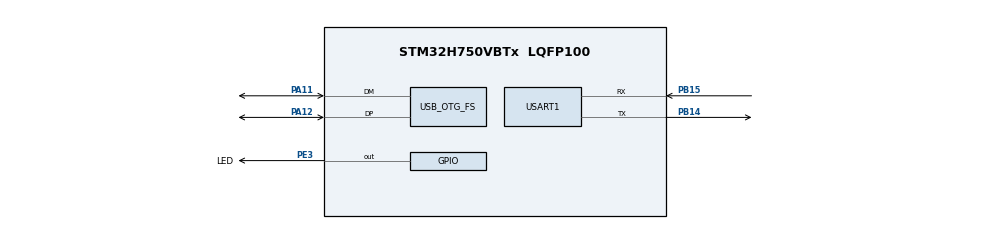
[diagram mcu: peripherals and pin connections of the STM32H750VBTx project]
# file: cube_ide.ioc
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FREERTOS.Tasks01=defaultTask,24,512,StartDefaultTask,Default,NULL,Dynamic,NULL,NULL
FREERTOS.configMINIMAL_STACK_SIZE=256
FREERTOS.configUSE_NEWLIB_REENTRANT=1
Mcu.Family=STM32H7
Mcu.Name=STM32H750VBTx
Mcu.Package=LQFP100
NVIC.OTG_FS_IRQn=true\:5\:0\:false\:false\:true\:true\:false\:true\:true
NVIC.PriorityGroup=NVIC_PRIORITYGROUP_4
PA11.Mode=Device_Only
PA11.Signal=USB_OTG_FS_DM
PA12.Mode=Device_Only
PA12.Signal=USB_OTG_FS_DP
PA13\ (JTMS/SWDIO).Mode=Serial_Wire
PA13\ (JTMS/SWDIO).Signal=DEBUG_JTMS-SWDIO
PA14\ (JTCK/SWCLK).Mode=Serial_Wire
PA14\ (JTCK/SWCLK).Signal=DEBUG_JTCK-SWCLK
PB14.Mode=Asynchronous
PB14.Signal=USART1_TX
PB15.Mode=Asynchronous
PB15.Signal=USART1_RX
PE3.GPIO_Label=LED
PE3.Signal=GPIO_Output
PH0-OSC_IN\ (PH0).Mode=HSE-External-Oscillator
PH0-OSC_IN\ (PH0).Signal=RCC_OSC_IN
PH1-OSC_OUT\ (PH1).Mode=HSE-External-Oscillator
PH1-OSC_OUT\ (PH1).Signal=RCC_OSC_OUT
ProjectManager.HeapSize=0x1000
ProjectManager.StackSize=0x400
ProjectManager.TargetToolchain=STM32CubeIDE
RCC.ADCFreq_Value=50000000
RCC.APB1Freq_Value=120000000
RCC.APB2Freq_Value=120000000
RCC.APB3Freq_Value=120000000
RCC.APB4Freq_Value=120000000
RCC.CortexFreq_Value=60000000
RCC.Cortex_Div=SYSTICK_CLKSOURCE_HCLK_DIV8
RCC.DIVM1=5
RCC.DIVM2=1
RCC.DIVM3=5
RCC.DIVN1=192
RCC.DIVN2=4
RCC.DIVN3=96
RCC.DIVQ3=10
RCC.HCLKFreq_Value=120000000
RCC.HPRE=RCC_HCLK_DIV4
RCC.PLL2FRACN=0
RCC.PLL3FRACN=0
RCC.PLLFRACN=0
RCC.PLLSourceVirtual=RCC_PLLSOURCE_HSE
RCC.ProductRev=revV
RCC.SYSCLKFreq_VALUE=480000000
RCC.SYSCLKSource=RCC_SYSCLKSOURCE_PLLCLK
RCC.USBCLockSelection=RCC_USBCLKSOURCE_PLL3
RCC.USBFreq_Value=48000000
USART1.VirtualMode-Asynchronous=VM_ASYNC
USB_DEVICE.CLASS_NAME_FS=CDC
USB_DEVICE.VirtualMode-CDC_FS=Cdc
USB_DEVICE.VirtualModeFS=Cdc_FS
USB_OTG_FS.VirtualMode=Device_Only
VP_FREERTOS_VS_CMSIS_V2.Mode=CMSIS_V2
VP_USB_DEVICE_VS_USB_DEVICE_CDC_FS.Mode=CDC_FS
board=custom

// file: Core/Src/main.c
/* USER CODE BEGIN Header */
/**
  ******************************************************************************
  * @file           : main.c
  * @brief          : Main program body
  ******************************************************************************
  * @attention
  *
  * Copyright (c) 2023 STMicroelectronics.
  * All rights reserved.
  *
  * This software is licensed under terms that can be found in the LICENSE file
  * in the root directory of this software component.
  * If no LICENSE file comes with this software, it is provided AS-IS.
  *
  ******************************************************************************
  */
/* USER CODE END Header */
#include "main.h"
#include "cmsis_os.h"
#include "usart.h"
#include "usb_device.h"
#include "gpio.h"

void SystemClock_Config(void);
void MX_FREERTOS_Init(void);

/* USER CODE BEGIN 0 */

void SysTick_Handler();
/* USER CODE END 0 */

int main(void)
{

  /* MCU Configuration--------------------------------------------------------*/

  /* Reset of all peripherals, Initializes the Flash interface and the Systick. */
  HAL_Init();

  /* Configure the system clock */
  SystemClock_Config();

  /* Initialize all configured peripherals */
  MX_GPIO_Init();
  MX_USART1_UART_Init();

  /* Init scheduler */
  osKernelInitialize();  /* Call init function for freertos objects (in freertos.c) */
  MX_FREERTOS_Init();

  /* Start scheduler */
  osKernelStart();
  /* We should never get here as control is now taken by the scheduler */
  /* Infinite loop */
  while (1)
  {

  }
}

void SystemClock_Config(void)
{
  RCC_OscInitTypeDef RCC_OscInitStruct = {0};
  RCC_ClkInitTypeDef RCC_ClkInitStruct = {0};

  /** Supply configuration update enable
  */
  HAL_PWREx_ConfigSupply(PWR_LDO_SUPPLY);

  /** Configure the main internal regulator output voltage
  */
  __HAL_PWR_VOLTAGESCALING_CONFIG(PWR_REGULATOR_VOLTAGE_SCALE1);

  while(!__HAL_PWR_GET_FLAG(PWR_FLAG_VOSRDY)) {}

  /** Initializes the RCC Oscillators according to the specified parameters
  * in the RCC_OscInitTypeDef structure.
  */
  RCC_OscInitStruct.OscillatorType = RCC_OSCILLATORTYPE_HSE;
  RCC_OscInitStruct.HSEState = RCC_HSE_ON;
  RCC_OscInitStruct.PLL.PLLState = RCC_PLL_ON;
  RCC_OscInitStruct.PLL.PLLSource = RCC_PLLSOURCE_HSE;
  RCC_OscInitStruct.PLL.PLLM = 5;
  RCC_OscInitStruct.PLL.PLLN = 160;
  RCC_OscInitStruct.PLL.PLLP = 2;
  RCC_OscInitStruct.PLL.PLLQ = 2;
  RCC_OscInitStruct.PLL.PLLR = 2;
  RCC_OscInitStruct.PLL.PLLRGE = RCC_PLL1VCIRANGE_2;
  RCC_OscInitStruct.PLL.PLLVCOSEL = RCC_PLL1VCOWIDE;
  RCC_OscInitStruct.PLL.PLLFRACN = 0;
  if (HAL_RCC_OscConfig(&RCC_OscInitStruct) != HAL_OK)
  {
    Error_Handler();
  }

  /** Initializes the CPU, AHB and APB buses clocks
  */
  RCC_ClkInitStruct.ClockType = RCC_CLOCKTYPE_HCLK|RCC_CLOCKTYPE_SYSCLK
                              |RCC_CLOCKTYPE_PCLK1|RCC_CLOCKTYPE_PCLK2
                              |RCC_CLOCKTYPE_D3PCLK1|RCC_CLOCKTYPE_D1PCLK1;
  RCC_ClkInitStruct.SYSCLKSource = RCC_SYSCLKSOURCE_PLLCLK;
  RCC_ClkInitStruct.SYSCLKDivider = RCC_SYSCLK_DIV1;
  RCC_ClkInitStruct.AHBCLKDivider = RCC_HCLK_DIV4;
  RCC_ClkInitStruct.APB3CLKDivider = RCC_APB3_DIV1;
  RCC_ClkInitStruct.APB1CLKDivider = RCC_APB1_DIV1;
  RCC_ClkInitStruct.APB2CLKDivider = RCC_APB2_DIV1;
  RCC_ClkInitStruct.APB4CLKDivider = RCC_APB4_DIV1;

  if (HAL_RCC_ClockConfig(&RCC_ClkInitStruct, FLASH_LATENCY_1) != HAL_OK)
  {
    Error_Handler();
  }
}

void Error_Handler(void)
{
  __disable_irq();
  while (1)
  {
  }
}
